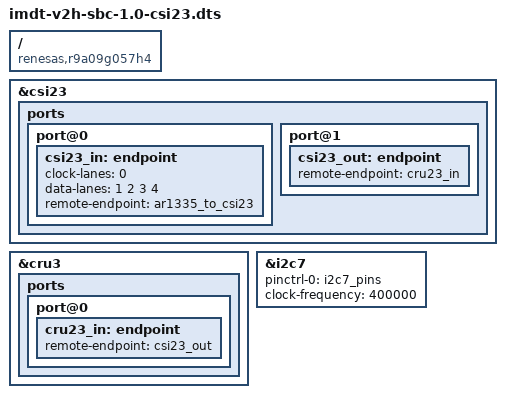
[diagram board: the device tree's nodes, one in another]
/dts-v1/;
/plugin/;

/ {
	compatible = "renesas,r9a09g057h4", "renesas,r9a09g057";
	
	// Enable CSI23 controller
	fragment@0 {
		target = <&csi23>;
		__overlay__ {
			status = "okay";
			ports {
				port@0 {
					csi23_in: endpoint {
						clock-lanes = <0>;
						data-lanes = <1 2 3 4>;
						remote-endpoint = <&ar1335_to_csi23>;
					};
				};
				port@1 {
					csi23_out: endpoint {
						remote-endpoint = <&cru23_in>;
					};
				};
			};
		};
	};

	// Enable CRU3 controller
	fragment@1 {
		target = <&cru3>;
		__overlay__ {
			status = "okay";
			ports {
				port@0 {
					cru23_in: endpoint {
						remote-endpoint = <&csi23_out>;
					};
				};
			};
		};
	};

	// Enable I2C7
	fragment@2 {
		target = <&i2c7>;
		__overlay__ {
			pinctrl-0 = <&i2c7_pins>;
			pinctrl-names = "default";
			clock-frequency = <400000>;
			status = "okay";
		};
	};
};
